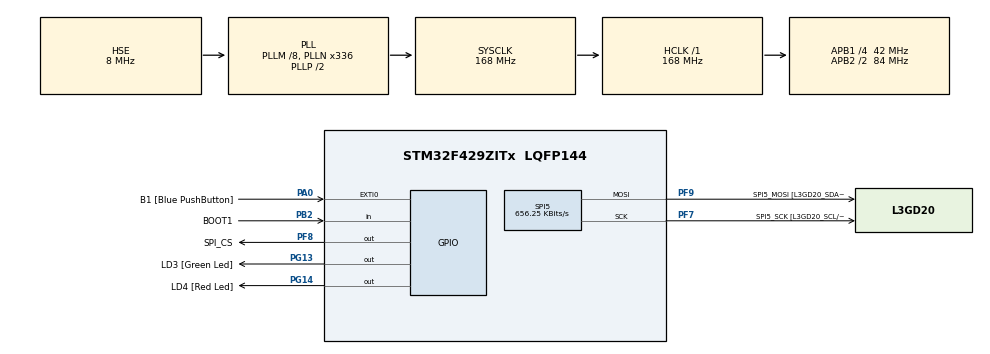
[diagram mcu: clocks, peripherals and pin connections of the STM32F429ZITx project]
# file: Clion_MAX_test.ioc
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Dma.Request0=SPI5_TX
Dma.SPI5_TX.0.Direction=DMA_MEMORY_TO_PERIPH
Dma.SPI5_TX.0.FIFOMode=DMA_FIFOMODE_DISABLE
Dma.SPI5_TX.0.Instance=DMA2_Stream4
Dma.SPI5_TX.0.MemDataAlignment=DMA_MDATAALIGN_HALFWORD
Dma.SPI5_TX.0.MemInc=DMA_MINC_ENABLE
Dma.SPI5_TX.0.Mode=DMA_NORMAL
Dma.SPI5_TX.0.PeriphDataAlignment=DMA_PDATAALIGN_HALFWORD
Dma.SPI5_TX.0.PeriphInc=DMA_PINC_DISABLE
Dma.SPI5_TX.0.Priority=DMA_PRIORITY_LOW
FREERTOS.INCLUDE_vTaskDelayUntil=1
FREERTOS.Tasks01=defaultTask,0,128,StartDefaultTask,Default,NULL,Dynamic,NULL,NULL;myTaskLD3,0,128,StartTaskLD3,Default,NULL,Dynamic,NULL,NULL;myTaskLD4,0,128,StartTaskLD4,Default,NULL,Dynamic,NULL,NULL
Mcu.Family=STM32F4
Mcu.Name=STM32F429ZITx
Mcu.Package=LQFP144
NVIC.DMA2_Stream4_IRQn=true\:5\:0\:false\:false\:true\:true\:false
NVIC.PriorityGroup=NVIC_PRIORITYGROUP_4
NVIC.SPI5_IRQn=true\:5\:0\:false\:false\:true\:true\:true
NVIC.TIM8_UP_TIM13_IRQn=true\:0\:0\:false\:false\:true\:false\:false
NVIC.TimeBase=TIM8_UP_TIM13_IRQn
NVIC.TimeBaseIP=TIM8
PA0/WKUP.GPIO_Label=B1 [Blue PushButton]
PA0/WKUP.GPIO_ModeDefaultEXTI=GPIO_MODE_EVT_RISING
PA0/WKUP.GPIO_PuPd=GPIO_NOPULL
PA0/WKUP.Signal=GPXTI0
PA13.GPIO_Label=SWDIO
PA13.Mode=Serial_Wire
PA13.Signal=SYS_JTMS-SWDIO
PA14.GPIO_Label=SWCLK
PA14.Mode=Serial_Wire
PA14.Signal=SYS_JTCK-SWCLK
PB2/BOOT1.GPIO_Label=BOOT1
PB2/BOOT1.GPIO_Mode=GPIO_MODE_INPUT
PB2/BOOT1.GPIO_PuPd=GPIO_NOPULL
PB2/BOOT1.Signal=GPIO_Input
PF7.GPIO_Label=SPI5_SCK [L3GD20_SCL/SPC]
PF7.GPIO_Mode=GPIO_MODE_AF_PP
PF7.GPIO_PuPd=GPIO_NOPULL
PF7.GPIO_Speed=GPIO_SPEED_FREQ_LOW
PF7.Mode=TX_Only_Simplex_Unidirect_Master
PF7.Signal=SPI5_SCK
PF8.GPIO_Label=SPI_CS
PF8.GPIO_ModeDefaultOutputPP=GPIO_MODE_OUTPUT_OD
PF8.PinState=GPIO_PIN_SET
PF8.Signal=GPIO_Output
PF9.GPIO_Label=SPI5_MOSI [L3GD20_SDA/SDI/SDO]
PF9.GPIO_Mode=GPIO_MODE_AF_PP
PF9.GPIO_PuPd=GPIO_NOPULL
PF9.GPIO_Speed=GPIO_SPEED_FREQ_LOW
PF9.Mode=TX_Only_Simplex_Unidirect_Master
PF9.Signal=SPI5_MOSI
PG13.GPIO_Label=LD3 [Green Led]
PG13.GPIO_Mode=GPIO_MODE_OUTPUT_PP
PG13.GPIO_PuPd=GPIO_NOPULL
PG13.GPIO_Speed=GPIO_SPEED_FREQ_LOW
PG13.Signal=GPIO_Output
PG14.GPIO_Label=LD4 [Red Led]
PG14.GPIO_Mode=GPIO_MODE_OUTPUT_PP
PG14.GPIO_PuPd=GPIO_NOPULL
PG14.GPIO_Speed=GPIO_SPEED_FREQ_LOW
PG14.Signal=GPIO_Output
PH0/OSC_IN.Mode=HSE-External-Oscillator
PH0/OSC_IN.Signal=RCC_OSC_IN
PH1/OSC_OUT.Mode=HSE-External-Oscillator
PH1/OSC_OUT.Signal=RCC_OSC_OUT
ProjectManager.HeapSize=0x200
ProjectManager.StackSize=0x400
ProjectManager.TargetToolchain=SW4STM32
RCC.48MHZClocksFreq_Value=48000000
RCC.AHBFreq_Value=168000000
RCC.APB1CLKDivider=RCC_HCLK_DIV4
RCC.APB1Freq_Value=42000000
RCC.APB1TimFreq_Value=84000000
RCC.APB2CLKDivider=RCC_HCLK_DIV2
RCC.APB2Freq_Value=84000000
RCC.APB2TimFreq_Value=168000000
RCC.CortexFreq_Value=168000000
RCC.HCLKFreq_Value=168000000
RCC.HSE_VALUE=8000000
RCC.HSI_VALUE=16000000
RCC.LSE_VALUE=32768
RCC.PLLM=8
RCC.PLLN=336
RCC.PLLQ=7
RCC.PLLSAIN=260
RCC.PLLSourceVirtual=RCC_PLLSOURCE_HSE
RCC.SYSCLKFreq_VALUE=168000000
RCC.SYSCLKSource=RCC_SYSCLKSOURCE_PLLCLK
RCC.VCOOutputFreq_Value=336000000
SPI5.BaudRatePrescaler=SPI_BAUDRATEPRESCALER_128
SPI5.CalculateBaudRate=656.25 KBits/s
SPI5.DataSize=SPI_DATASIZE_16BIT
SPI5.Direction=SPI_DIRECTION_2LINES
SPI5.Mode=SPI_MODE_MASTER
SPI5.VirtualType=VM_MASTER
VP_FREERTOS_VS_ENABLE.Mode=Enabled
VP_SYS_VS_tim8.Mode=TIM8
board=32F429IDISCOVERY

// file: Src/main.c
/**
  ******************************************************************************
  * @file           : main.c
  * @brief          : Main program body
  ******************************************************************************
  * This notice applies to any and all portions of this file
  * that are not between comment pairs USER CODE BEGIN and
  * USER CODE END. Other portions of this file, whether
  * inserted by the user or by software development tools
  * are owned by their respective copyright owners.
  *
  * Copyright (c) 2018 STMicroelectronics International N.V.
  * All rights reserved.
  *
  * Redistribution and use in source and binary forms, with or without
  * modification, are permitted, provided that the following conditions are met:
  *
  * 1. Redistribution of source code must retain the above copyright notice,
  *    this list of conditions and the following disclaimer.
  * 2. Redistributions in binary form must reproduce the above copyright notice,
  *    this list of conditions and the following disclaimer in the documentation
  *    and/or other materials provided with the distribution.
  * 3. Neither the name of STMicroelectronics nor the names of other
  *    contributors to this software may be used to endorse or promote products
  *    derived from this software without specific written permission.
  * 4. This software, including modifications and/or derivative works of this
  *    software, must execute solely and exclusively on microcontroller or
  *    microprocessor devices manufactured by or for STMicroelectronics.
  * 5. Redistribution and use of this software other than as permitted under
  *    this license is void and will automatically terminate your rights under
  *    this license.
  *
  * THIS SOFTWARE IS PROVIDED BY STMICROELECTRONICS AND CONTRIBUTORS "AS IS"
  * AND ANY EXPRESS, IMPLIED OR STATUTORY WARRANTIES, INCLUDING, BUT NOT
  * LIMITED TO, THE IMPLIED WARRANTIES OF MERCHANTABILITY, FITNESS FOR A
  * PARTICULAR PURPOSE AND NON-INFRINGEMENT OF THIRD PARTY INTELLECTUAL PROPERTY
  * RIGHTS ARE DISCLAIMED TO THE FULLEST EXTENT PERMITTED BY LAW. IN NO EVENT
  * SHALL STMICROELECTRONICS OR CONTRIBUTORS BE LIABLE FOR ANY DIRECT, INDIRECT,
  * INCIDENTAL, SPECIAL, EXEMPLARY, OR CONSEQUENTIAL DAMAGES (INCLUDING, BUT NOT
  * LIMITED TO, PROCUREMENT OF SUBSTITUTE GOODS OR SERVICES; LOSS OF USE, DATA,
  * OR PROFITS; OR BUSINESS INTERRUPTION) HOWEVER CAUSED AND ON ANY THEORY OF
  * LIABILITY, WHETHER IN CONTRACT, STRICT LIABILITY, OR TORT (INCLUDING
  * NEGLIGENCE OR OTHERWISE) ARISING IN ANY WAY OUT OF THE USE OF THIS SOFTWARE,
  * EVEN IF ADVISED OF THE POSSIBILITY OF SUCH DAMAGE.
  *
  ******************************************************************************
  */
#include "main.h"
#include "stm32f4xx_hal.h"
#include "cmsis_os.h"
#include "dma.h"
#include "spi.h"
#include "gpio.h"

/* USER CODE BEGIN Includes */
#include "SEGGER_RTT.h"
/* USER CODE END Includes */

/* USER CODE BEGIN PV */
/* Private variables ---------------------------------------------------------*/

/* USER CODE END PV */

void SystemClock_Config(void);
void MX_FREERTOS_Init(void);

/* USER CODE BEGIN PFP */
/* Private function prototypes -----------------------------------------------*/

/* USER CODE END PFP */

int main(void)
{
  /* USER CODE BEGIN 1 */
SEGGER_RTT_WriteString(0, "Начало программы main");
  /* USER CODE END 1 */

  /* MCU Configuration----------------------------------------------------------*/

  /* Reset of all peripherals, Initializes the Flash interface and the Systick. */
  HAL_Init();

  /* Configure the system clock */
  SystemClock_Config();

  /* Initialize all configured peripherals */
  MX_GPIO_Init();
  MX_DMA_Init();
  MX_SPI5_Init();

  /* Call init function for freertos objects (in freertos.c) */
  MX_FREERTOS_Init();

  /* Start scheduler */
  osKernelStart();

  /* We should never get here as control is now taken by the scheduler */

  /* Infinite loop */
  while (1)
  {

  }

}

void SystemClock_Config(void)
{

  RCC_OscInitTypeDef RCC_OscInitStruct;
  RCC_ClkInitTypeDef RCC_ClkInitStruct;

    /**Configure the main internal regulator output voltage
    */
  __HAL_RCC_PWR_CLK_ENABLE();

  __HAL_PWR_VOLTAGESCALING_CONFIG(PWR_REGULATOR_VOLTAGE_SCALE1);

    /**Initializes the CPU, AHB and APB busses clocks
    */
  RCC_OscInitStruct.OscillatorType = RCC_OSCILLATORTYPE_HSE;
  RCC_OscInitStruct.HSEState = RCC_HSE_ON;
  RCC_OscInitStruct.PLL.PLLState = RCC_PLL_ON;
  RCC_OscInitStruct.PLL.PLLSource = RCC_PLLSOURCE_HSE;
  RCC_OscInitStruct.PLL.PLLM = 8;
  RCC_OscInitStruct.PLL.PLLN = 336;
  RCC_OscInitStruct.PLL.PLLP = RCC_PLLP_DIV2;
  RCC_OscInitStruct.PLL.PLLQ = 7;
  if (HAL_RCC_OscConfig(&RCC_OscInitStruct) != HAL_OK)
  {
    _Error_Handler(__FILE__, __LINE__);
  }

    /**Initializes the CPU, AHB and APB busses clocks
    */
  RCC_ClkInitStruct.ClockType = RCC_CLOCKTYPE_HCLK|RCC_CLOCKTYPE_SYSCLK
                              |RCC_CLOCKTYPE_PCLK1|RCC_CLOCKTYPE_PCLK2;
  RCC_ClkInitStruct.SYSCLKSource = RCC_SYSCLKSOURCE_PLLCLK;
  RCC_ClkInitStruct.AHBCLKDivider = RCC_SYSCLK_DIV1;
  RCC_ClkInitStruct.APB1CLKDivider = RCC_HCLK_DIV4;
  RCC_ClkInitStruct.APB2CLKDivider = RCC_HCLK_DIV2;

  if (HAL_RCC_ClockConfig(&RCC_ClkInitStruct, FLASH_LATENCY_5) != HAL_OK)
  {
    _Error_Handler(__FILE__, __LINE__);
  }

    /**Configure the Systick interrupt time
    */
  HAL_SYSTICK_Config(HAL_RCC_GetHCLKFreq()/1000);

    /**Configure the Systick
    */
  HAL_SYSTICK_CLKSourceConfig(SYSTICK_CLKSOURCE_HCLK);

  /* SysTick_IRQn interrupt configuration */
  HAL_NVIC_SetPriority(SysTick_IRQn, 15, 0);
}

void HAL_TIM_PeriodElapsedCallback(TIM_HandleTypeDef *htim)
{
  if (htim->Instance == TIM8) {
    HAL_IncTick();
  }
}

void _Error_Handler(char *file, int line)
{
  while(1)
  {
  }
}

/************************ (C) COPYRIGHT STMicroelectronics *****END OF FILE****/

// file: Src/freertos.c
/**
  ******************************************************************************
  * File Name          : freertos.c
  * Description        : Code for freertos applications
  ******************************************************************************
  * This notice applies to any and all portions of this file
  * that are not between comment pairs USER CODE BEGIN and
  * USER CODE END. Other portions of this file, whether
  * inserted by the user or by software development tools
  * are owned by their respective copyright owners.
  *
  * Copyright (c) 2018 STMicroelectronics International N.V.
  * All rights reserved.
  *
  * Redistribution and use in source and binary forms, with or without
  * modification, are permitted, provided that the following conditions are met:
  *
  * 1. Redistribution of source code must retain the above copyright notice,
  *    this list of conditions and the following disclaimer.
  * 2. Redistributions in binary form must reproduce the above copyright notice,
  *    this list of conditions and the following disclaimer in the documentation
  *    and/or other materials provided with the distribution.
  * 3. Neither the name of STMicroelectronics nor the names of other
  *    contributors to this software may be used to endorse or promote products
  *    derived from this software without specific written permission.
  * 4. This software, including modifications and/or derivative works of this
  *    software, must execute solely and exclusively on microcontroller or
  *    microprocessor devices manufactured by or for STMicroelectronics.
  * 5. Redistribution and use of this software other than as permitted under
  *    this license is void and will automatically terminate your rights under
  *    this license.
  *
  * THIS SOFTWARE IS PROVIDED BY STMICROELECTRONICS AND CONTRIBUTORS "AS IS"
  * AND ANY EXPRESS, IMPLIED OR STATUTORY WARRANTIES, INCLUDING, BUT NOT
  * LIMITED TO, THE IMPLIED WARRANTIES OF MERCHANTABILITY, FITNESS FOR A
  * PARTICULAR PURPOSE AND NON-INFRINGEMENT OF THIRD PARTY INTELLECTUAL PROPERTY
  * RIGHTS ARE DISCLAIMED TO THE FULLEST EXTENT PERMITTED BY LAW. IN NO EVENT
  * SHALL STMICROELECTRONICS OR CONTRIBUTORS BE LIABLE FOR ANY DIRECT, INDIRECT,
  * INCIDENTAL, SPECIAL, EXEMPLARY, OR CONSEQUENTIAL DAMAGES (INCLUDING, BUT NOT
  * LIMITED TO, PROCUREMENT OF SUBSTITUTE GOODS OR SERVICES; LOSS OF USE, DATA,
  * OR PROFITS; OR BUSINESS INTERRUPTION) HOWEVER CAUSED AND ON ANY THEORY OF
  * LIABILITY, WHETHER IN CONTRACT, STRICT LIABILITY, OR TORT (INCLUDING
  * NEGLIGENCE OR OTHERWISE) ARISING IN ANY WAY OUT OF THE USE OF THIS SOFTWARE,
  * EVEN IF ADVISED OF THE POSSIBILITY OF SUCH DAMAGE.
  *
  ******************************************************************************
  */

#include "FreeRTOS.h"
#include "task.h"
#include "cmsis_os.h"

/* USER CODE BEGIN Includes */
#include "stm32f4xx_hal_gpio.h"
//#include "MAX7219.h"
//#include "MAX7219_MatrixDisplay.h"
#include "main.h"
#include "example.h"
#include "stm32f4xx_hal.h"
/* USER CODE END Includes */

osThreadId defaultTaskHandle;
osThreadId myTaskLD3Handle;
osThreadId myTaskLD4Handle;

/* USER CODE BEGIN Variables */

osThreadId myTaskDisplayHandler;
//extern SPI_HandleTypeDef hspi5;

/* USER CODE END Variables */

void StartDefaultTask(void const * argument);
void StartTaskLD3(void const * argument);
void StartTaskLD4(void const * argument);

void MX_FREERTOS_Init(void); /* (MISRA C 2004 rule 8.1) */

/* USER CODE BEGIN FunctionPrototypes */
//extern void StartTaskDisplay(void const* argument);
/* USER CODE END FunctionPrototypes */

/* Hook prototypes */

/* Init FreeRTOS */

void MX_FREERTOS_Init(void) {

  /* Create the thread(s) */
  /* definition and creation of defaultTask */
  osThreadDef(defaultTask, StartDefaultTask, osPriorityNormal, 0, 128);
  defaultTaskHandle = osThreadCreate(osThread(defaultTask), NULL);

  /* definition and creation of myTaskLD3 */
  osThreadDef(myTaskLD3, StartTaskLD3, osPriorityNormal, 0, 128);
  myTaskLD3Handle = osThreadCreate(osThread(myTaskLD3), NULL);

  /* definition and creation of myTaskLD4 */
  osThreadDef(myTaskLD4, StartTaskLD4, osPriorityNormal, 0, 128);
  myTaskLD4Handle = osThreadCreate(osThread(myTaskLD4), NULL);

  /* USER CODE BEGIN RTOS_THREADS */
  /* add threads, ... */
  osThreadDef(myTaskDisplay, StartTaskDisplay,osPriorityNormal,0,128);
  myTaskDisplayHandler=osThreadCreate(osThread(myTaskDisplay),NULL);

  /* USER CODE END RTOS_THREADS */

}

/* StartDefaultTask function */
void StartDefaultTask(void const * argument)
{

  for(;;)
  {
    osDelay(1);
  }
}

/* StartTaskLD3 function */
void StartTaskLD3(void const * argument)
{
  /* USER CODE BEGIN StartTaskLD3 */
  /* Infinite loop */
  for(;;)
  {
  /**/  HAL_GPIO_TogglePin(LD3_GPIO_Port, LD3_Pin);
    osDelay(250);
  }
  /* USER CODE END StartTaskLD3 */
}

/* StartTaskLD4 function */
void StartTaskLD4(void const * argument)
{
  /* USER CODE BEGIN StartTaskLD4 */
  /* Infinite loop */
  for(;;)
  {
/*    HAL_GPIO_TogglePin(LD4_GPIO_Port, LD4_Pin);*/
    osDelay(50);
  }

  /* USER CODE END StartTaskLD4 */
}

/************************ (C) COPYRIGHT STMicroelectronics *****END OF FILE****/
